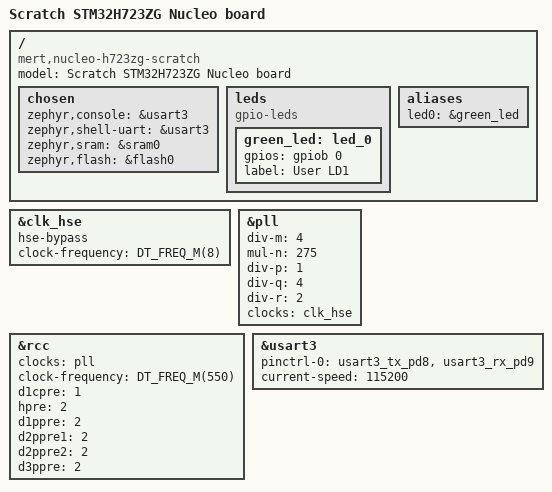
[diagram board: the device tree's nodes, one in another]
/* SPDX-License-Identifier: Apache-2.0 */

/dts-v1/;
#include <st/h7/stm32h723Xg.dtsi>
#include <st/h7/stm32h723zgtx-pinctrl.dtsi>
#include <zephyr/dt-bindings/gpio/gpio.h>

/ {
	model = "Scratch STM32H723ZG Nucleo board";
	compatible = "mert,nucleo-h723zg-scratch";

	chosen {
		zephyr,console = &usart3;
		zephyr,shell-uart = &usart3;
		zephyr,sram = &sram0;
		zephyr,flash = &flash0;
	};

	leds {
		compatible = "gpio-leds";

		green_led: led_0 {
			gpios = <&gpiob 0 GPIO_ACTIVE_HIGH>;
			label = "User LD1";
		};
	};

	aliases {
		led0 = &green_led;
	};
};

&clk_hse {
	hse-bypass;
	clock-frequency = <DT_FREQ_M(8)>;
	status = "okay";
};

&pll {
	div-m = <4>;
	mul-n = <275>;
	div-p = <1>;
	div-q = <4>;
	div-r = <2>;
	clocks = <&clk_hse>;
	status = "okay";
};

&rcc {
	clocks = <&pll>;
	clock-frequency = <DT_FREQ_M(550)>;
	d1cpre = <1>;
	hpre = <2>;
	d1ppre = <2>;
	d2ppre1 = <2>;
	d2ppre2 = <2>;
	d3ppre = <2>;
};

&usart3 {
	pinctrl-0 = <&usart3_tx_pd8 &usart3_rx_pd9>;
	pinctrl-names = "default";
	current-speed = <115200>;
	status = "okay";
};
